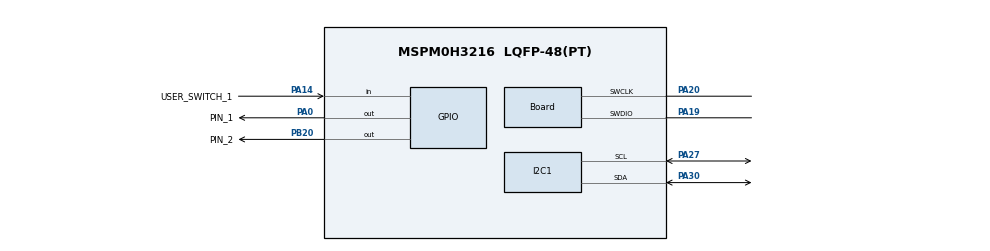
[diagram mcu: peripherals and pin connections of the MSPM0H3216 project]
//@cliArgs --device "MSPM0H321X" --package "LQFP-48(PT)" --part "Default"
//@v2CliArgs --device "MSPM0H3216" --package "LQFP-48(PT)"
// @cliArgs --board /ti/boards/LP_MSPM0H3216 --rtos nortos

/**
 * Import the modules used in this configuration.
 */
const GPIO          = scripting.addModule("/ti/driverlib/GPIO", {}, false);
const GPIO1         = GPIO.addInstance();
const GPIO2         = GPIO.addInstance();
const GPIO3         = GPIO.addInstance();
const I2C           = scripting.addModule("/ti/driverlib/I2C", {}, false);
const I2C1          = I2C.addInstance();
const ProjectConfig = scripting.addModule("/ti/project_config/ProjectConfig");

/**
 * Write custom configuration values to the imported modules.
 */
GPIO1.$name                         = "GPIO_LED1";
GPIO1.associatedPins[0].$name       = "PIN_1";
GPIO1.associatedPins[0].pin.$assign = "PA0";

const Board                       = scripting.addModule("/ti/driverlib/Board", {}, false);
Board.peripheral.$assign          = "DEBUGSS";
Board.peripheral.swclkPin.$assign = "PA20";
Board.peripheral.swdioPin.$assign = "PA19";

GPIO2.$name                              = "GPIO_SWITCHES";
GPIO2.associatedPins[0].direction        = "INPUT";
GPIO2.associatedPins[0].interruptEn      = true;
GPIO2.associatedPins[0].polarity         = "FALL";
GPIO2.associatedPins[0].internalResistor = "PULL_UP";
GPIO2.associatedPins[0].$name            = "USER_SWITCH_1";
GPIO2.associatedPins[0].pin.$assign      = "PA14";

GPIO3.$name                         = "GPIO_LED2";
GPIO3.associatedPins[0].$name       = "PIN_2";
GPIO3.associatedPins[0].pin.$assign = "PB20";

I2C1.basicEnableTarget                 = true;
I2C1.basicTargetAddress                = 0x48;
I2C1.intTarget                         = ["RXFIFO_TRIGGER"];
I2C1.$name                             = "I2C";
I2C1.peripheral.$assign                = "I2C0";
I2C1.peripheral.sdaPin.$assign         = "PA30";
I2C1.peripheral.sclPin.$assign         = "PA27";
I2C1.sdaPinConfig.enableConfig         = true;
I2C1.sdaPinConfig.internalResistor     = "PULL_UP";
I2C1.sclPinConfig.enableConfig         = true;
I2C1.sclPinConfig.internalResistor     = "PULL_UP";

const SYSCTL              = scripting.addModule("/ti/driverlib/SYSCTL", {}, false);
SYSCTL.peripheral.$assign = "SYSCTL";

ProjectConfig.genLinker          = false;
ProjectConfig.migrationCondition = true;
scripting.suppress("All four File Generation options must be enabled in order to guarantee Device Migration support\\. If an option is disabled, the user must manually configure that setting on its own file\\.", ProjectConfig);
